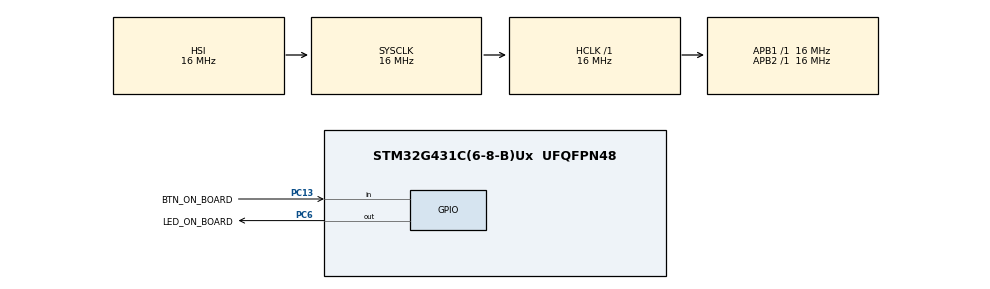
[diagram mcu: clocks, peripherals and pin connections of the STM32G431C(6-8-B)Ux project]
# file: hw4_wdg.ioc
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IWDG.Prescaler=IWDG_PRESCALER_256
IWDG.Reload=625
Mcu.Family=STM32G4
Mcu.Name=STM32G431C(6-8-B)Ux
Mcu.Package=UFQFPN48
NVIC.PriorityGroup=NVIC_PRIORITYGROUP_4
PA13.Mode=Serial_Wire
PA13.Signal=SYS_JTMS-SWDIO
PA14.Mode=Serial_Wire
PA14.Signal=SYS_JTCK-SWCLK
PC13.GPIO_Label=BTN_ON_BOARD
PC13.GPIO_PuPd=GPIO_PULLDOWN
PC13.Signal=GPIO_Input
PC14-OSC32_IN.Mode=LSE-External-Oscillator
PC14-OSC32_IN.Signal=RCC_OSC32_IN
PC15-OSC32_OUT.Mode=LSE-External-Oscillator
PC15-OSC32_OUT.Signal=RCC_OSC32_OUT
PC6.GPIO_Label=LED_ON_BOARD
PC6.Signal=GPIO_Output
PF0-OSC_IN.Mode=HSE-External-Oscillator
PF0-OSC_IN.Signal=RCC_OSC_IN
PF1-OSC_OUT.Mode=HSE-External-Oscillator
PF1-OSC_OUT.Signal=RCC_OSC_OUT
ProjectManager.HeapSize=0x200
ProjectManager.StackSize=0x400
ProjectManager.TargetToolchain=STM32CubeIDE
RCC.AHBFreq_Value=16000000
RCC.APB1Freq_Value=16000000
RCC.APB1TimFreq_Value=16000000
RCC.APB2Freq_Value=16000000
RCC.APB2TimFreq_Value=16000000
RCC.CortexFreq_Value=16000000
RCC.EXTERNAL_CLOCK_VALUE=12288000
RCC.HCLKFreq_Value=16000000
RCC.HSE_VALUE=8000000
RCC.HSI48_VALUE=48000000
RCC.HSI_VALUE=16000000
RCC.SYSCLKFreq_VALUE=16000000
RCC.USBFreq_Value=64000000
RCC.VCOOutputFreq_Value=128000000
VP_IWDG_VS_IWDG.Mode=IWDG_Activate
VP_SYS_VS_DBSignals.Mode=DisableDeadBatterySignals
board=custom

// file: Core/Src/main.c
/* USER CODE BEGIN Header */
/**
  ******************************************************************************
  * @file           : main.c
  * @brief          : Main program body
  ******************************************************************************
  * @attention
  *
  * Copyright (c) 2025 STMicroelectronics.
  * All rights reserved.
  *
  * This software is licensed under terms that can be found in the LICENSE file
  * in the root directory of this software component.
  * If no LICENSE file comes with this software, it is provided AS-IS.
  *
  ******************************************************************************
  */
/* USER CODE END Header */
#include "main.h"

/* USER CODE BEGIN Includes */
#include "stm32g4xx_ll_rcc.h"
/* USER CODE END Includes */

/* USER CODE BEGIN PD */

struct
{
  uint8_t PINRST;  /*!< PIN reset flag */
  uint8_t BORRST;  /*!< BOR reset flag */
  uint8_t SFTRST;  /*!< Software Reset flag */
  uint8_t IWDGRST; /*!< Independent Watchdog reset flag */
  uint8_t WWDGRST; /*!< Window watchdog reset flag */
  uint8_t LPWRRST; /*!< Low-Power reset flag */
}reset_flags;

/* USER CODE END PD */

IWDG_HandleTypeDef hiwdg;

void SystemClock_Config(void);
static void MX_GPIO_Init(void);
static void MX_IWDG_Init(void);

int main(void)
{

  /* MCU Configuration--------------------------------------------------------*/

  /* Reset of all peripherals, Initializes the Flash interface and the Systick. */
  HAL_Init();

  /* USER CODE BEGIN Init */
  reset_flags.PINRST =  LL_RCC_IsActiveFlag_PINRST();
  reset_flags.BORRST =  LL_RCC_IsActiveFlag_BORRST();
  reset_flags.SFTRST =  LL_RCC_IsActiveFlag_SFTRST();
  reset_flags.IWDGRST =  LL_RCC_IsActiveFlag_IWDGRST();
  reset_flags.WWDGRST =  LL_RCC_IsActiveFlag_WWDGRST();
  reset_flags.LPWRRST =  LL_RCC_IsActiveFlag_LPWRRST();

  LL_RCC_ClearResetFlags();

  /* USER CODE END Init */

  /* Configure the system clock */
  SystemClock_Config();

  /* Initialize all configured peripherals */
  MX_GPIO_Init();
  MX_IWDG_Init();

  /* Infinite loop */
  /* USER CODE BEGIN WHILE */

  HAL_GPIO_WritePin(LED_ON_BOARD_GPIO_Port, LED_ON_BOARD_Pin, GPIO_PIN_SET);
  HAL_Delay(3000);

  HAL_IWDG_Refresh(&hiwdg);

  while (1)
  {

    if(HAL_GPIO_ReadPin(BTN_ON_BOARD_GPIO_Port, BTN_ON_BOARD_Pin))
    {
      HAL_NVIC_SystemReset();
    }
//      HAL_NVIC_SystemReset();

    HAL_GPIO_TogglePin(LED_ON_BOARD_GPIO_Port, LED_ON_BOARD_Pin);
    HAL_Delay(200);
    /* USER CODE END WHILE */

  }
}

void SystemClock_Config(void)
{
  RCC_OscInitTypeDef RCC_OscInitStruct = {0};
  RCC_ClkInitTypeDef RCC_ClkInitStruct = {0};

  /** Configure the main internal regulator output voltage
  */
  HAL_PWREx_ControlVoltageScaling(PWR_REGULATOR_VOLTAGE_SCALE1);

  /** Initializes the RCC Oscillators according to the specified parameters
  * in the RCC_OscInitTypeDef structure.
  */
  RCC_OscInitStruct.OscillatorType = RCC_OSCILLATORTYPE_HSI|RCC_OSCILLATORTYPE_LSI;
  RCC_OscInitStruct.HSIState = RCC_HSI_ON;
  RCC_OscInitStruct.HSICalibrationValue = RCC_HSICALIBRATION_DEFAULT;
  RCC_OscInitStruct.LSIState = RCC_LSI_ON;
  RCC_OscInitStruct.PLL.PLLState = RCC_PLL_NONE;
  if (HAL_RCC_OscConfig(&RCC_OscInitStruct) != HAL_OK)
  {
    Error_Handler();
  }

  /** Initializes the CPU, AHB and APB buses clocks
  */
  RCC_ClkInitStruct.ClockType = RCC_CLOCKTYPE_HCLK|RCC_CLOCKTYPE_SYSCLK
                              |RCC_CLOCKTYPE_PCLK1|RCC_CLOCKTYPE_PCLK2;
  RCC_ClkInitStruct.SYSCLKSource = RCC_SYSCLKSOURCE_HSI;
  RCC_ClkInitStruct.AHBCLKDivider = RCC_SYSCLK_DIV1;
  RCC_ClkInitStruct.APB1CLKDivider = RCC_HCLK_DIV1;
  RCC_ClkInitStruct.APB2CLKDivider = RCC_HCLK_DIV1;

  if (HAL_RCC_ClockConfig(&RCC_ClkInitStruct, FLASH_LATENCY_0) != HAL_OK)
  {
    Error_Handler();
  }
}

static void MX_IWDG_Init(void)
{

  hiwdg.Instance = IWDG;
  hiwdg.Init.Prescaler = IWDG_PRESCALER_256;
  hiwdg.Init.Window = 4095;
  hiwdg.Init.Reload = 625;
  if (HAL_IWDG_Init(&hiwdg) != HAL_OK)
  {
    Error_Handler();
  }

}

static void MX_GPIO_Init(void)
{
  GPIO_InitTypeDef GPIO_InitStruct = {0};

  /* GPIO Ports Clock Enable */
  __HAL_RCC_GPIOC_CLK_ENABLE();
  __HAL_RCC_GPIOF_CLK_ENABLE();
  __HAL_RCC_GPIOA_CLK_ENABLE();

  /*Configure GPIO pin Output Level */
  HAL_GPIO_WritePin(LED_ON_BOARD_GPIO_Port, LED_ON_BOARD_Pin, GPIO_PIN_RESET);

  /*Configure GPIO pin : BTN_ON_BOARD_Pin */
  GPIO_InitStruct.Pin = BTN_ON_BOARD_Pin;
  GPIO_InitStruct.Mode = GPIO_MODE_INPUT;
  GPIO_InitStruct.Pull = GPIO_PULLDOWN;
  HAL_GPIO_Init(BTN_ON_BOARD_GPIO_Port, &GPIO_InitStruct);

  /*Configure GPIO pin : LED_ON_BOARD_Pin */
  GPIO_InitStruct.Pin = LED_ON_BOARD_Pin;
  GPIO_InitStruct.Mode = GPIO_MODE_OUTPUT_PP;
  GPIO_InitStruct.Pull = GPIO_NOPULL;
  GPIO_InitStruct.Speed = GPIO_SPEED_FREQ_LOW;
  HAL_GPIO_Init(LED_ON_BOARD_GPIO_Port, &GPIO_InitStruct);

}

void Error_Handler(void)
{
  __disable_irq();
  while (1)
  {
  }
}
